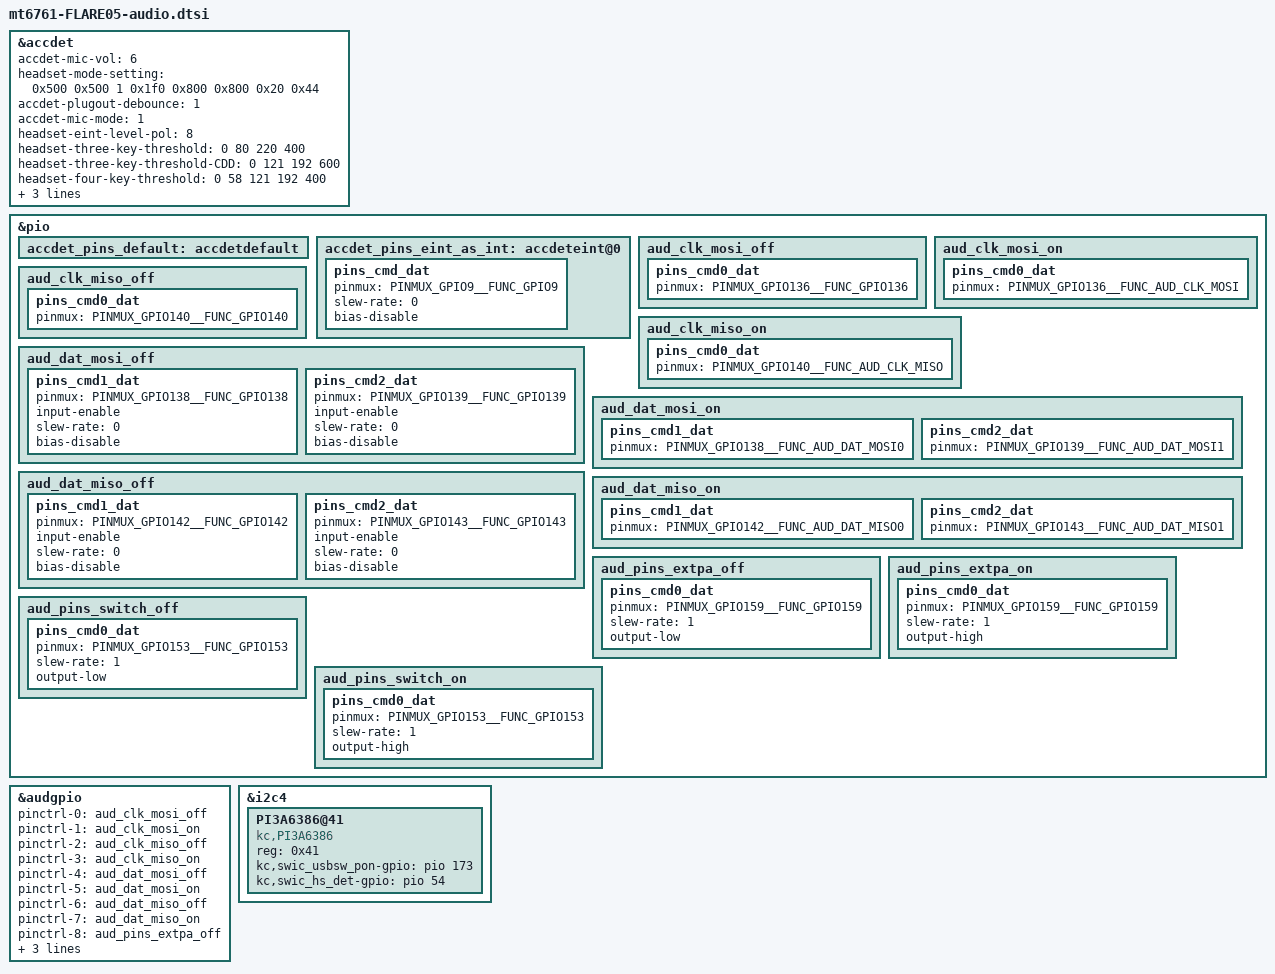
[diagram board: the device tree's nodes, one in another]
/*
 * This software is contributed or developed by KYOCERA Corporation.
 * (C) 2022 KYOCERA Corporation
 *
 * This program is free software; you can redistribute it and/or modify
 * it under the terms of the GNU General Public License version 2 and
 * only version 2 as published by the Free Software Foundation.
 *
 * This program is distributed in the hope that it will be useful,
 * but WITHOUT ANY WARRANTY; without even the implied warranty of
 * MERCHANTABILITY or FITNESS FOR A PARTICULAR PURPOSE.  See the
 * GNU General Public License for more details.
 */

&accdet {
        accdet-mic-vol = <6>;
        headset-mode-setting = <0x500 0x500 1 0x1f0 0x800 0x800 0x20 0x44>;
        accdet-plugout-debounce = <1>;
        accdet-mic-mode = <1>;
        headset-eint-level-pol = <8>;
        headset-three-key-threshold = <0 80 220 400>;
        headset-three-key-threshold-CDD = <0 121 192 600>;
        headset-four-key-threshold = <0 58 121 192 400>;
        pinctrl-names = "default", "state_eint_as_int";
        pinctrl-0 = <&accdet_pins_default>;
        pinctrl-1 = <&accdet_pins_eint_as_int>;
        status = "okay";
        eint-comp-thresh = <1>;
};
&pio {
        accdet_pins_default: accdetdefault {
        };
        accdet_pins_eint_as_int: accdeteint@0 {
                pins_cmd_dat {
                        pinmux = <PINMUX_GPIO9__FUNC_GPIO9>;
                        slew-rate = <0>;
                        bias-disable;
                };
        };
};

&audgpio {
        pinctrl-names = "aud_clk_mosi_off",
                        "aud_clk_mosi_on",
                        "aud_clk_miso_off",
                        "aud_clk_miso_on",
                        "aud_dat_mosi_off",
                        "aud_dat_mosi_on",
                        "aud_dat_miso_off",
                        "aud_dat_miso_on",
                        "extamp-pulllow",
                        "extamp-pullhigh",
                        "rcvspk-pulllow",
                        "rcvspk-pullhigh";
        pinctrl-0 = <&aud_clk_mosi_off>;
        pinctrl-1 = <&aud_clk_mosi_on>;
        pinctrl-2 = <&aud_clk_miso_off>;
        pinctrl-3 = <&aud_clk_miso_on>;
        pinctrl-4 = <&aud_dat_mosi_off>;
        pinctrl-5 = <&aud_dat_mosi_on>;
        pinctrl-6 = <&aud_dat_miso_off>;
        pinctrl-7 = <&aud_dat_miso_on>;
        pinctrl-8 = <&aud_pins_extpa_off>;
        pinctrl-9 = <&aud_pins_extpa_on>;
        pinctrl-10 = <&aud_pins_switch_off>;
        pinctrl-11 = <&aud_pins_switch_on>;
        status = "okay";
};

&pio {
        aud_clk_mosi_off: aud_clk_mosi_off {
                pins_cmd0_dat {
                        pinmux = <PINMUX_GPIO136__FUNC_GPIO136>;
                };
        };

        aud_clk_mosi_on: aud_clk_mosi_on {
                pins_cmd0_dat {
                        pinmux = <PINMUX_GPIO136__FUNC_AUD_CLK_MOSI>;
                };
        };

        aud_clk_miso_off: aud_clk_miso_off {
                pins_cmd0_dat {
                        pinmux = <PINMUX_GPIO140__FUNC_GPIO140>;
                };
        };

        aud_clk_miso_on: aud_clk_miso_on {
                pins_cmd0_dat {
                        pinmux = <PINMUX_GPIO140__FUNC_AUD_CLK_MISO>;
                };
        };

        aud_dat_mosi_off: aud_dat_mosi_off {
		pins_cmd1_dat {
                        pinmux = <PINMUX_GPIO138__FUNC_GPIO138>;
                        input-enable;
                        slew-rate = <0>;
                        bias-disable;
                };
                pins_cmd2_dat {
                        pinmux = <PINMUX_GPIO139__FUNC_GPIO139>;
                        input-enable;
                        slew-rate = <0>;
                        bias-disable;
                };
        };

        aud_dat_mosi_on: aud_dat_mosi_on {
                pins_cmd1_dat {
                        pinmux = <PINMUX_GPIO138__FUNC_AUD_DAT_MOSI0>;
                };
                pins_cmd2_dat {
                        pinmux = <PINMUX_GPIO139__FUNC_AUD_DAT_MOSI1>;
                };
        };

        aud_dat_miso_off: aud_dat_miso_off {
                pins_cmd1_dat {
                        pinmux = <PINMUX_GPIO142__FUNC_GPIO142>;
                        input-enable;
                        slew-rate = <0>;
                        bias-disable;
                };
                pins_cmd2_dat {
                        pinmux = <PINMUX_GPIO143__FUNC_GPIO143>;
                        input-enable;
                        slew-rate = <0>;
                        bias-disable;
                };
        };

        aud_dat_miso_on: aud_dat_miso_on {
                pins_cmd1_dat {
                        pinmux = <PINMUX_GPIO142__FUNC_AUD_DAT_MISO0>;
                };
                pins_cmd2_dat {
                        pinmux = <PINMUX_GPIO143__FUNC_AUD_DAT_MISO1>;
                };
        };

        aud_pins_extpa_off: aud_pins_extpa_off {
                pins_cmd0_dat {
                        pinmux = <PINMUX_GPIO159__FUNC_GPIO159>;
			slew-rate = <1>;
                        output-low;
                };
        };

        aud_pins_extpa_on: aud_pins_extpa_on {
                pins_cmd0_dat {
                        pinmux = <PINMUX_GPIO159__FUNC_GPIO159>;
                        slew-rate = <1>;
                        output-high;
                };
        };

       aud_pins_switch_off: aud_pins_switch_off {
                pins_cmd0_dat {
                        pinmux = <PINMUX_GPIO153__FUNC_GPIO153>;
                        slew-rate = <1>;
                        output-low;
                };
        };

        aud_pins_switch_on: aud_pins_switch_on {
                pins_cmd0_dat {
                        pinmux = <PINMUX_GPIO153__FUNC_GPIO153>;
                        slew-rate = <1>;
                        output-high;
                };
        };
};

&i2c4 {
	PI3A6386@41 {
		status = "okay";
		compatible = "kc,PI3A6386";
		reg = <0x41>;
		kc,swic_usbsw_pon-gpio = <&pio 173 0>;
		kc,swic_hs_det-gpio = <&pio 54 0>;
	};
};
